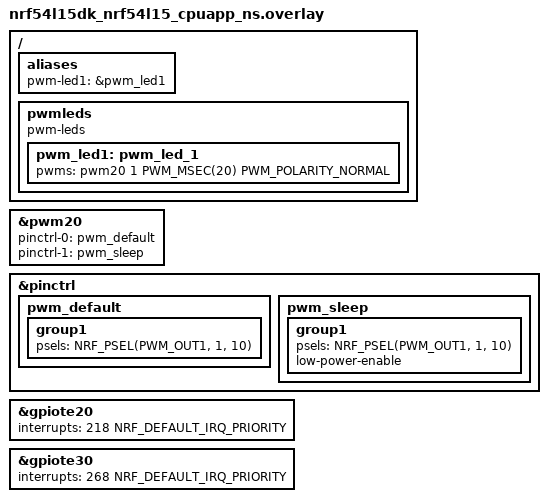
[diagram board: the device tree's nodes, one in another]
/*
 * Copyright (c) 2024 Nordic Semiconductor ASA
 *
 * SPDX-License-Identifier: LicenseRef-Nordic-5-Clause
 */

/ {
	aliases {
		// Configure PWM module for led1 (LED2 on the board)
		pwm-led1 = &pwm_led1;
	};

	pwmleds {
		compatible = "pwm-leds";
		pwm_led1: pwm_led_1 {
			pwms = <&pwm20 1 PWM_MSEC(20) PWM_POLARITY_NORMAL>;
		};
	};
};

&pwm20 {
	status = "okay";
	pinctrl-0 = <&pwm_default>;
	pinctrl-1 = <&pwm_sleep>;
	pinctrl-names = "default", "sleep";
};

&pinctrl {
	pwm_default: pwm_default {
		group1 {
			psels = <NRF_PSEL(PWM_OUT1, 1, 10)>;
		};
	};
	pwm_sleep: pwm_sleep {
		group1 {
			psels = <NRF_PSEL(PWM_OUT1, 1, 10)>;
			low-power-enable;
		};
	};
};

// Change IRQ ids to handle button interrupts.

// The default values for nRF54L15 are 219 and 269,
// but with TF-M they are reserved for the secure domain
// (218 and 268 are reserved for the non-secure domain).
&gpiote20 {
	interrupts = <218 NRF_DEFAULT_IRQ_PRIORITY>;
};

&gpiote30 {
	interrupts = <268 NRF_DEFAULT_IRQ_PRIORITY>;
};
